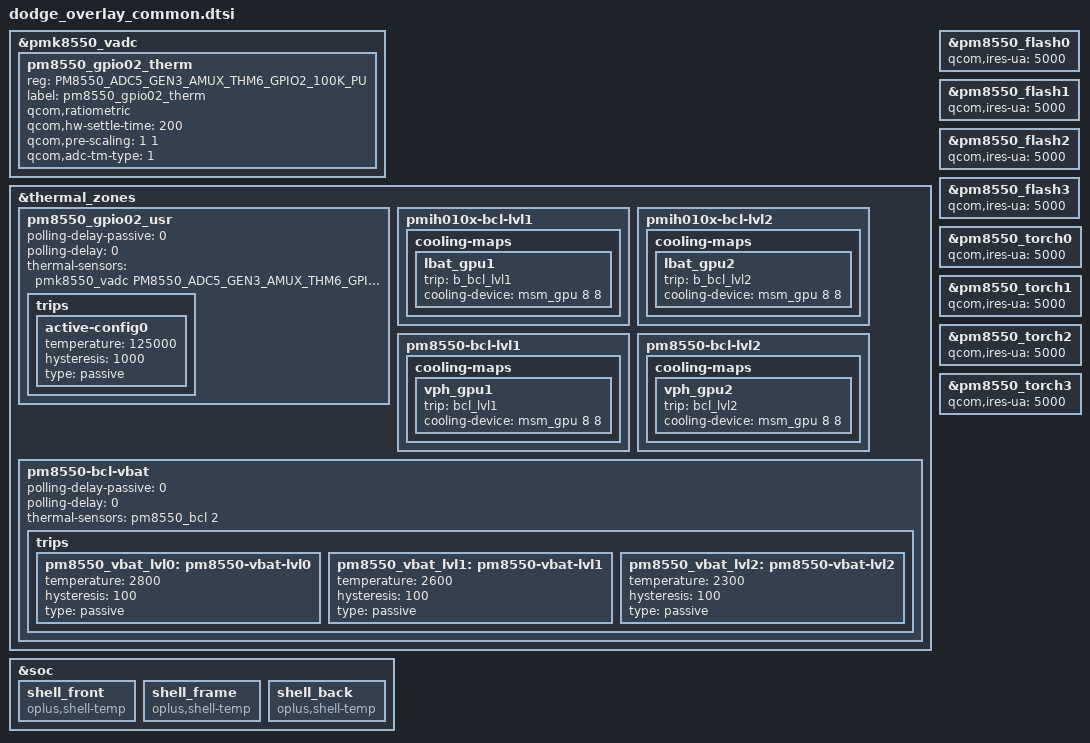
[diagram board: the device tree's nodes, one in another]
&pmk8550_vadc {
	pm8550_gpio02_therm {
		reg = <PM8550_ADC5_GEN3_AMUX_THM6_GPIO2_100K_PU>;
		label = "pm8550_gpio02_therm";
		qcom,ratiometric;
		qcom,hw-settle-time = <200>;
		qcom,pre-scaling = <1 1>;
		qcom,adc-tm-type = <1>;
	};

};

&thermal_zones {
	pm8550_gpio02_usr {
		polling-delay-passive = <0>;
		polling-delay = <0>;
		thermal-sensors = <&pmk8550_vadc PM8550_ADC5_GEN3_AMUX_THM6_GPIO2_100K_PU>;
		trips {
			active-config0 {
				temperature = <125000>;
				hysteresis = <1000>;
				type = "passive";
			};
		};
	};

	pmih010x-bcl-lvl1 {
		cooling-maps {
			lbat_gpu1 {
				trip = <&b_bcl_lvl1>;
				cooling-device = <&msm_gpu 8 8>;
			};
		};
	};

	pmih010x-bcl-lvl2 {
		cooling-maps {
			lbat_gpu2 {
				trip = <&b_bcl_lvl2>;
				cooling-device = <&msm_gpu 8 8>;
			};
		};
	};

	pm8550-bcl-lvl1 {
		cooling-maps {
			vph_gpu1 {
				trip = <&bcl_lvl1>;
				cooling-device = <&msm_gpu 8 8>;
			};
		};
	};

	pm8550-bcl-lvl2 {
		cooling-maps {
			vph_gpu2 {
				trip = <&bcl_lvl2>;
				cooling-device = <&msm_gpu 8 8>;
			};
		};
	};

	pm8550-bcl-vbat {
		polling-delay-passive = <0>;
		polling-delay = <0>;
		thermal-sensors = <&pm8550_bcl 2>;

		trips {
			pm8550_vbat_lvl0: pm8550-vbat-lvl0 {
				temperature = <2800>;
				hysteresis = <100>;
				type = "passive";
			};

			pm8550_vbat_lvl1: pm8550-vbat-lvl1 {
				temperature = <2600>;
				hysteresis = <100>;
				type = "passive";
			};

			pm8550_vbat_lvl2: pm8550-vbat-lvl2 {
				temperature = <2300>;
				hysteresis = <100>;
				type = "passive";
			};
		};
	};
};

&pm8550_flash0 {
	qcom,ires-ua = <5000>;
};

&pm8550_flash1 {
	qcom,ires-ua = <5000>;
};

&pm8550_flash2 {
	qcom,ires-ua = <5000>;
};

&pm8550_flash3 {
	qcom,ires-ua = <5000>;
};

&pm8550_torch0 {
	qcom,ires-ua = <5000>;
};

&pm8550_torch1 {
	qcom,ires-ua = <5000>;
};

&pm8550_torch2 {
	qcom,ires-ua = <5000>;
};

&pm8550_torch3 {
	qcom,ires-ua = <5000>;
};

&soc {
	//#ifdef OPLUS_FEATURE_THERMAL_HORAE
	shell_front {
		compatible = "oplus,shell-temp";
	};

	shell_frame {
		compatible = "oplus,shell-temp";
	};

	shell_back {
		compatible = "oplus,shell-temp";
	};
	//#endif /* OPLUS_FEATURE_THERMAL_HORAE */

};
